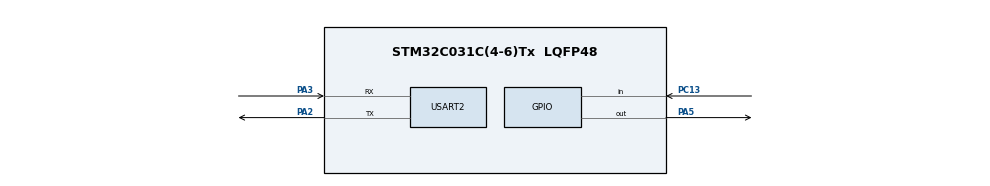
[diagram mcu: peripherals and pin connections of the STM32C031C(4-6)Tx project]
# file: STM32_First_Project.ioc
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Mcu.Family=STM32C0
Mcu.Name=STM32C031C(4-6)Tx
Mcu.Package=LQFP48
NUCLEO-C031C6.BUTTON=1
NUCLEO-C031C6.LD4=true
NUCLEO-C031C6.VCP=false
PA13.GPIO_Label=DEBUG_SWDIO
PA13.Signal=DEBUG_SWDIO
PA14-BOOT0.GPIO_Label=DEBUG_SWCLK
PA14-BOOT0.Signal=DEBUG_SWCLK
PA2.Mode=Asynchronous
PA2.Signal=USART2_TX
PA3.Mode=Asynchronous
PA3.Signal=USART2_RX
PA5.GPIO_ModeDefaultOutputPP=GPIO_MODE_OUTPUT_PP
PA5.PinState=GPIO_PIN_RESET
PA5.Signal=GPIO_Output
PC13.GPIO_PuPd=GPIO_NOPULL
PC13.Signal=GPIO_Input
PC14-OSCX_IN\ (PC14).GPIO_Label=RCC_OSCX_IN
PC14-OSCX_IN\ (PC14).Mode=LSE-External-Oscillator
PC14-OSCX_IN\ (PC14).Signal=RCC_OSCX_IN
PC15-OSCX_OUT\ (PC15).GPIO_Label=RCC_OSCX_OUT
PC15-OSCX_OUT\ (PC15).Mode=LSE-External-Oscillator
PC15-OSCX_OUT\ (PC15).Signal=RCC_OSCX_OUT
PF0-OSC_IN\ (PF0).GPIO_Label=RCC_OSC_IN
PF0-OSC_IN\ (PF0).Mode=HSE-External-Oscillator
PF0-OSC_IN\ (PF0).Signal=RCC_OSC_IN
PF1-OSC_OUT\ (PF1).GPIO_Label=RCC_OSC_OUT
PF1-OSC_OUT\ (PF1).Mode=HSE-External-Oscillator
PF1-OSC_OUT\ (PF1).Signal=RCC_OSC_OUT
ProjectManager.HeapSize=0x200
ProjectManager.StackSize=0x400
ProjectManager.TargetToolchain=STM32CubeIDE
RCC.ADCFreq_Value=48000000
RCC.AHBFreq_Value=48000000
RCC.CortexFreq_Value=48000000
RCC.EXTERNAL_CLOCK_VALUE=12288000
RCC.HCLKFreq_Value=48000000
RCC.HSE_VALUE=48000000
RCC.HSISYSCLKDivider=RCC_HSI_DIV1
RCC.HSI_VALUE=48000000
RCC.SYSCLKFreq_VALUE=48000000
RCC.SYSCLKSource=RCC_SYSCLKSOURCE_HSE
USART2.VirtualMode-Asynchronous=VM_ASYNC
VP_NUCLEO-C031C6_VS_BSP_COMMON.Mode=COMMON
board=NUCLEO-C031C6

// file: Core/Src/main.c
/* USER CODE BEGIN Header */
/**
  ******************************************************************************
  * @file           : main.c
  * @brief          : Main program body
  ******************************************************************************
  * @attention
  *
  * Copyright (c) 2026 STMicroelectronics.
  * All rights reserved.
  *
  * This software is licensed under terms that can be found in the LICENSE file
  * in the root directory of this software component.
  * If no LICENSE file comes with this software, it is provided AS-IS.
  *
  ******************************************************************************
  */
/* USER CODE END Header */
#include "main.h"

/* USER CODE BEGIN Includes */
#include "stm32c0xx.h"
/* USER CODE END Includes */

UART_HandleTypeDef huart2;

/* USER CODE BEGIN PV */
volatile uint32_t ms_ticks = 0;
uint8_t rx_data;
/* USER CODE END PV */

void SystemClock_Config(void);
static void MX_GPIO_Init(void);
static void MX_USART2_UART_Init(void);

int main(void)
{

  /* MCU Configuration--------------------------------------------------------*/

  /* Reset of all peripherals, Initializes the Flash interface and the Systick. */
  HAL_Init();

  /* Configure the system clock */
  SystemClock_Config();

  /* Initialize all configured peripherals */
  MX_GPIO_Init();
  MX_USART2_UART_Init();
  /* USER CODE BEGIN 2 */
  uint8_t message[] = "STM32 UART Ready\r\n";

  HAL_UART_Transmit(&huart2,
                   message,
                   sizeof(message) - 1,
                   HAL_MAX_DELAY);
  /* GPIOC clock */
  /* USER CODE END 2 */

  /* Initialize leds */
  BSP_LED_Init(LED_GREEN);

  /* Initialize USER push-button, will be used to trigger an interrupt each time it's pressed.*/
  BSP_PB_Init(BUTTON_USER, BUTTON_MODE_EXTI);

  /* Infinite loop */
  while (1)
  {

    /* USER CODE BEGIN 3 */

	  if (HAL_UART_Receive(&huart2, &rx_data, 1, 10) == HAL_OK)
	      {
	          HAL_UART_Transmit(&huart2, &rx_data, 1, HAL_MAX_DELAY);
	      }
	  }

  /* USER CODE END 3 */
}

void SystemClock_Config(void)
{
  RCC_OscInitTypeDef RCC_OscInitStruct = {0};
  RCC_ClkInitTypeDef RCC_ClkInitStruct = {0};

  __HAL_FLASH_SET_LATENCY(FLASH_LATENCY_1);

  /** Initializes the RCC Oscillators according to the specified parameters
  * in the RCC_OscInitTypeDef structure.
  */
  RCC_OscInitStruct.OscillatorType = RCC_OSCILLATORTYPE_HSE;
  RCC_OscInitStruct.HSEState = RCC_HSE_ON;
  if (HAL_RCC_OscConfig(&RCC_OscInitStruct) != HAL_OK)
  {
    Error_Handler();
  }

  /** Initializes the CPU, AHB and APB buses clocks
  */
  RCC_ClkInitStruct.ClockType = RCC_CLOCKTYPE_HCLK|RCC_CLOCKTYPE_SYSCLK
                              |RCC_CLOCKTYPE_PCLK1;
  RCC_ClkInitStruct.SYSCLKSource = RCC_SYSCLKSOURCE_HSE;
  RCC_ClkInitStruct.SYSCLKDivider = RCC_SYSCLK_DIV1;
  RCC_ClkInitStruct.AHBCLKDivider = RCC_HCLK_DIV1;
  RCC_ClkInitStruct.APB1CLKDivider = RCC_APB1_DIV1;

  if (HAL_RCC_ClockConfig(&RCC_ClkInitStruct, FLASH_LATENCY_1) != HAL_OK)
  {
    Error_Handler();
  }
}

static void MX_USART2_UART_Init(void)
{

  huart2.Instance = USART2;
  huart2.Init.BaudRate = 115200;
  huart2.Init.WordLength = UART_WORDLENGTH_8B;
  huart2.Init.StopBits = UART_STOPBITS_1;
  huart2.Init.Parity = UART_PARITY_NONE;
  huart2.Init.Mode = UART_MODE_TX_RX;
  huart2.Init.HwFlowCtl = UART_HWCONTROL_NONE;
  huart2.Init.OverSampling = UART_OVERSAMPLING_16;
  huart2.Init.OneBitSampling = UART_ONE_BIT_SAMPLE_DISABLE;
  huart2.Init.ClockPrescaler = UART_PRESCALER_DIV1;
  huart2.AdvancedInit.AdvFeatureInit = UART_ADVFEATURE_NO_INIT;
  if (HAL_UART_Init(&huart2) != HAL_OK)
  {
    Error_Handler();
  }

}

static void MX_GPIO_Init(void)
{
  GPIO_InitTypeDef GPIO_InitStruct = {0};

  /* GPIO Ports Clock Enable */
  __HAL_RCC_GPIOC_CLK_ENABLE();
  __HAL_RCC_GPIOF_CLK_ENABLE();
  __HAL_RCC_GPIOA_CLK_ENABLE();

  /*Configure GPIO pin Output Level */
  HAL_GPIO_WritePin(GPIOA, GPIO_PIN_5, GPIO_PIN_RESET);

  /*Configure GPIO pin : PC13 */
  GPIO_InitStruct.Pin = GPIO_PIN_13;
  GPIO_InitStruct.Mode = GPIO_MODE_INPUT;
  GPIO_InitStruct.Pull = GPIO_NOPULL;
  HAL_GPIO_Init(GPIOC, &GPIO_InitStruct);

  /*Configure GPIO pin : PA5 */
  GPIO_InitStruct.Pin = GPIO_PIN_5;
  GPIO_InitStruct.Mode = GPIO_MODE_OUTPUT_PP;
  GPIO_InitStruct.Pull = GPIO_NOPULL;
  GPIO_InitStruct.Speed = GPIO_SPEED_FREQ_LOW;
  HAL_GPIO_Init(GPIOA, &GPIO_InitStruct);

}

void Error_Handler(void)
{
  __disable_irq();
  while (1)
  {
  }
}
